# AT32UC3C1512C device description
Architecture: AVR32_UC3; Family: AVR UC3
Registers are 32-bit, read-write, reset 0x0 unless marked. A register's access mark holds for its fields unless they carry their own. Offsets are from the block's base; [hi:lo] are bit positions; {n}, {i} and the like mark numbered series; 'fields as' and 'values as' point back to an identical list.

## TWIS — Two-wire Slave Interface
Instances: TWIS0 0xffff4000, TWIS1 0xffff4400, TWIS2 0xfffd3000
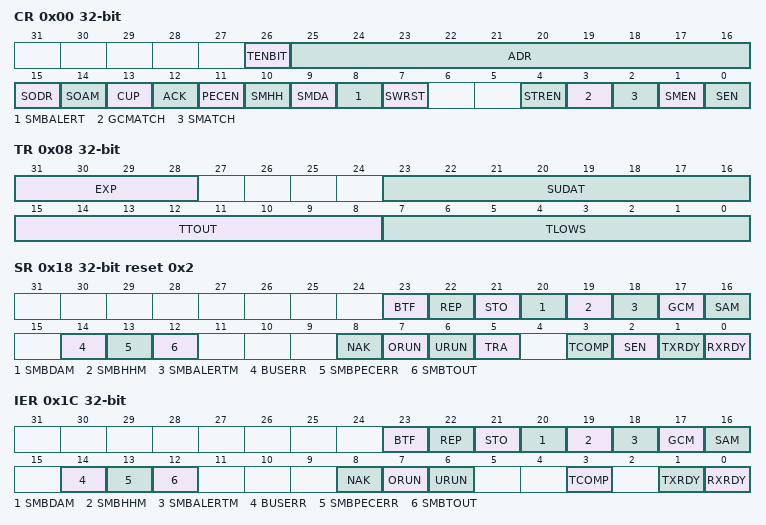
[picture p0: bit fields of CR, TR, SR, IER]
0x00 CR — Control Register
  [26] TENBIT — Ten Bit Address Match
  [25:16] ADR — Slave Address
  [15] SODR — Stretch Clock on Data Byte Reception
  [14] SOAM — Stretch Clock on Address Match
  [13] CUP — NBYTES Count Up
  [12] ACK — Slave Receiver Data Phase ACK Value
  [11] PECEN — Packet Error Checking Enable
  [10] SMHH — SMBus Host Header
  [9] SMDA — SMBus Default Address
  [8] SMBALERT — SMBus Alert
  [7] SWRST — Software Reset
  [4] STREN — Clock Stretch Enable
  [3] GCMATCH — General Call Address Match
  [2] SMATCH — Slave Address Match
  [1] SMEN — SMBus Mode Enable
  [0] SEN — Slave Enable
0x04 NBYTES
  [7:0] NBYTES — Number of Bytes to Transfer
0x08 TR — Timing Register
  [31:28] EXP — Clock Prescaler
  [23:16] SUDAT — Data Setup Cycles
  [15:8] TTOUT — SMBus Ttimeout Cycles
  [7:0] TLOWS — SMBus Tlow:sext Cycles
0x0C RHR ro — Receive Holding Register
  [7:0] RXDATA — Received Data Byte
0x10 THR wo — Transmit Holding Register
  [7:0] TXDATA — Data Byte to Transmit
0x14 PECR ro — Packet Error Check Register
  [7:0] PEC — Calculated PEC Value
0x18 SR ro reset 0x2 — Status Register
  [23] BTF — Byte Transfer Finished
  [22] REP — Repeated Start Received
  [21] STO — Stop Received
  [20] SMBDAM — SMBus Default Address Match
  [19] SMBHHM — SMBus Host Header Address Match
  [18] SMBALERTM — SMBus Alert Response Address Match
  [17] GCM — General Call Match
  [16] SAM — Slave Address Match
  [14] BUSERR — Bus Error
  [13] SMBPECERR — SMBus PEC Error
  [12] SMBTOUT — SMBus Timeout
  [8] NAK — NAK Received
  [7] ORUN — Overrun
  [6] URUN — Underrun
  [5] TRA — Transmitter Mode
  [3] TCOMP — Transmission Complete
  [2] SEN — Slave Enabled
  [1] TXRDY — TX Buffer Ready
  [0] RXRDY — RX Buffer Ready
0x1C IER wo — Interrupt Enable Register
  [23] BTF — Byte Transfer Finished
  [22] REP — Repeated Start Received
  [21] STO — Stop Received
  [20] SMBDAM — SMBus Default Address Match
  [19] SMBHHM — SMBus Host Header Address Match
  [18] SMBALERTM — SMBus Alert Response Address Match
  [17] GCM — General Call Match
  [16] SAM — Slave Address Match
  [14] BUSERR — Bus Error
  [13] SMBPECERR — SMBus PEC Error
  [12] SMBTOUT — SMBus Timeout
  [8] NAK — NAK Received
  [7] ORUN — Overrun
  [6] URUN — Underrun
  [3] TCOMP — Transmission Complete
  [1] TXRDY — TX Buffer Ready
  [0] RXRDY — RX Buffer Ready
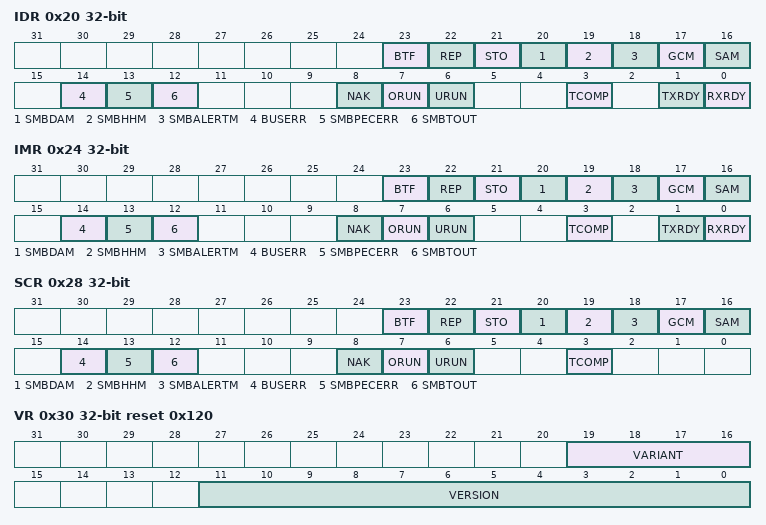
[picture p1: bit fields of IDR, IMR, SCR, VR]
0x20 IDR wo — Interrupt Disable Register
  fields as IER
0x24 IMR ro — Interrupt Mask Register
  fields as IER
0x28 SCR wo — Status Clear Register
  [23] BTF — Byte Transfer Finished
  [22] REP — Repeated Start Received
  [21] STO — Stop Received
  [20] SMBDAM — SMBus Default Address Match
  [19] SMBHHM — SMBus Host Header Address Match
  [18] SMBALERTM — SMBus Alert Response Address Match
  [17] GCM — General Call Match
  [16] SAM — Slave Address Match
  [14] BUSERR — Bus Error
  [13] SMBPECERR — SMBus PEC Error
  [12] SMBTOUT — SMBus Timeout
  [8] NAK — NAK Received
  [7] ORUN — Overrun
  [6] URUN — Underrun
  [3] TCOMP — Transmission Complete
0x2C PR ro — Parameter Register
0x30 VR ro reset 0x120 — Version Register
  [19:16] VARIANT — Variant Number
  [11:0] VERSION — Version Number

## WDT — Watchdog Timer
Instances: WDT 0xffff1000
Parameters: WDT_KEY_CONST=85
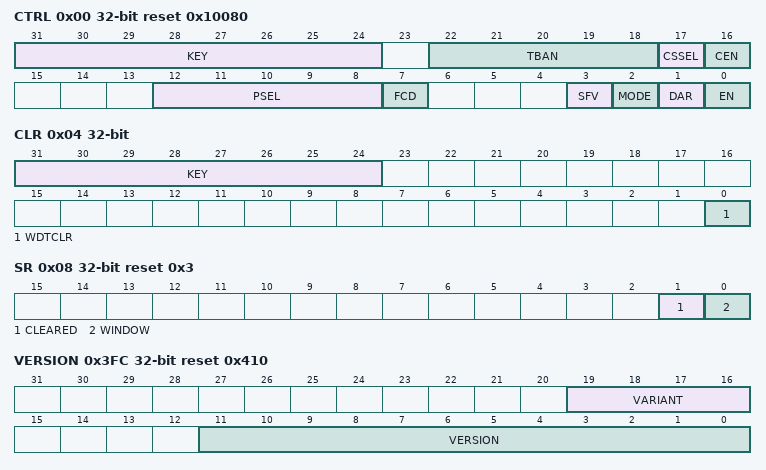
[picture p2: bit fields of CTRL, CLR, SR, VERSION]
0x00 CTRL reset 0x10080 — Control Register
  [31:24] KEY
  [22:18] TBAN — TBAN Prescale Select
  [17] CSSEL — Clock Source Selection
  [16] CEN — Clock Enable
  [12:8] PSEL — Timeout Prescale Select
  [7] FCD — WDT Fuse Calibration Done
  [3] SFV — WDT Store Final Value
  [2] MODE — WDT Mode
  [1] DAR — WDT Disable After Reset
  [0] EN — WDT Enable
0x04 CLR wo — Clear Register
  [31:24] KEY
  [0] WDTCLR — Clear WDT counter
0x08 SR ro reset 0x3 — Status Register
  [1] CLEARED — WDT cleared
  [0] WINDOW — WDT in window
0x3FC VERSION ro reset 0x410
  [19:16] VARIANT — Variant number
  [11:0] VERSION — Version number

## USERPAGE_FUSES — Fuses
Instances: USERPAGE_FUSES 0x80800000
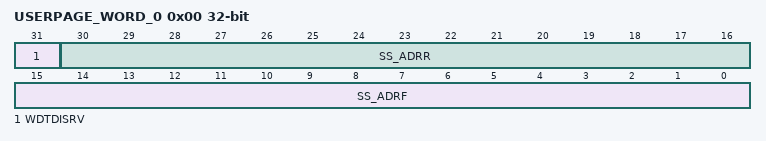
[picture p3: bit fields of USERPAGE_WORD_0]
0x00 USERPAGE_WORD_0 reset not defined
  [31] WDTDISRV — Watch dog timer auto disable at startup
    0=WDT_ENABLE (Watch dog timer is automatically enabled at startup); 1=WDT_DISABLE (Watch dog timer is not automatically enabled at startup)
  [30:16] SS_ADRR — Size of the CPU RAM controlled by the Secure State
  [15:0] SS_ADRF — Size of the Flash controlled by the Secure State

## FLASH_FUSES — Fuses
Instances: FUSES 0xFFFE0000 in fuses
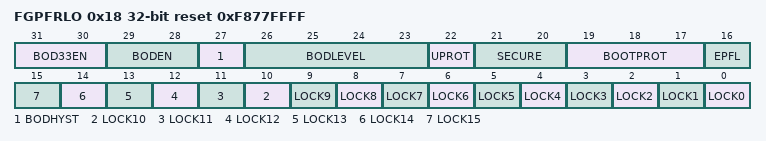
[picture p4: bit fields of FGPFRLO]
0x18 FGPFRLO reset 0xF877FFFF — Flash Controller General Purpose Fuse Register Low
  [31:30] BOD33EN — 3.3 V brownout detector enable
  [29:28] BODEN — Brownout detector enable
    0=BOD_DISABLED; 1=BOD_ENABLED_RESET_ENABLED (BOD18 enabled, BOD18 reset enabled); 2=BOD_ENABLED_RESET_DISABLED (BOD18 enabled, BOD18 reset disabled); 3=BOD_DISABLED2
  [27] BODHYST — Brownout detector hysteresis
    0=BODHYST_DISABLED (Disabled); 1=BODHYST_ENABLED (Enabled)
  [26:23] BODLEVEL — Brownout detector trigger level
    0=BOD_LEVEL_1V52 (BOD Level 1.38-1.52V); 5=BOD_LEVEL_1V58 (BOD Level 1.44-1.58V); 6=BOD_LEVEL_1V66 (BOD Level 1.48-1-66V); 7=BOD_LEVEL_1V68 (BOD Level 1.51-1.68V); 8=BOD_LEVEL_1V73 (BOD Level 1.55-1.73V); 9=BOD_LEVEL_1V79 (BOD Level 1.59-1.79V); 10=BOD_LEVEL_1V83 (BOD Level 1.64-1.83V)
  [22] UPROT — JTAG user protection
    1=UPROT_ENABLE (Enable JTAG user protection); 0=UPROT_DISABLE (Disable JTAG user protection)
  [21:20] SECURE — Secure State
    0=SSDIS (Secure state disabled); 1=SSEN_SSDEN (Secure enabled, secure state debug enabled); 2=SSEN_SSDDIS (Secure enabled, secure state debug disabled); 3=SSDIS (Secure state disabled)
  [19:17] BOOTPROT — Bootloader protection
    0=BOOTAREA_64KB (Boot area: 64 Kbyte); 1=BOOTAREA_32KB (Boot area: 32 Kbyte); 2=BOOTAREA_16KB (Boot area: 16 Kbyte); 3=BOOTAREA_8KB (Boot area: 8 Kbyte); 4=BOOTAREA_4KB (Boot area: 4 Kbyte); 5=BOOTAREA_2KB (Boot area: 2 Kbyte); 6=BOOTAREA_1KB (Boot area: 1 Kbyte); 7=BOOTAREA_0B (Boot area: 0 byte)
  [16] EPFL — External privileged fetch lock
    0=EPFL_LOCK (External privileged fetch locked); 1=EPFL_NO_LOCK (External privileged fetch not locked)
  [n] LOCK{n} (n=0..15)
Value list BOD33EN: 0=BOD33_DISABLED; 1=BOD33_ENABLED_RESET_ENABLED (BOD33 enabled, BOD33 reset enabled); 2=BOD33_ENABLED_RESET_DISABLED (BOD33 enabled, BOD33 reset disabled); 3=BOD33_DISABLED2
